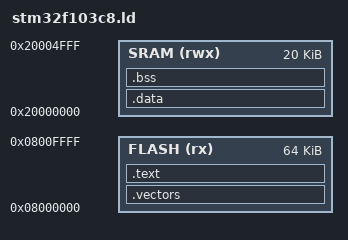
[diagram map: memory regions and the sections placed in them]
/* Minimal linker script for STM32F103C8T6 (64 KB Flash, 20 KB SRAM) */

MEMORY
{
    FLASH (rx)  : ORIGIN = 0x08000000, LENGTH = 64K
    SRAM  (rwx) : ORIGIN = 0x20000000, LENGTH = 20K
}

SECTIONS
{
    .vectors :
    {
        KEEP(*(.vectors))
    } > FLASH

    .text :
    {
        *(.text*)
        *(.rodata*)
    } > FLASH

    . = ALIGN(4);
    _etext = .;

    .data : AT (_etext)
    {
        _sdata = .;
        *(.data*)
        . = ALIGN(4);
        _edata = .;
    } > SRAM

    .bss :
    {
        _sbss = .;
        *(.bss*)
        *(COMMON)
        . = ALIGN(4);
        _ebss = .;
    } > SRAM
}
